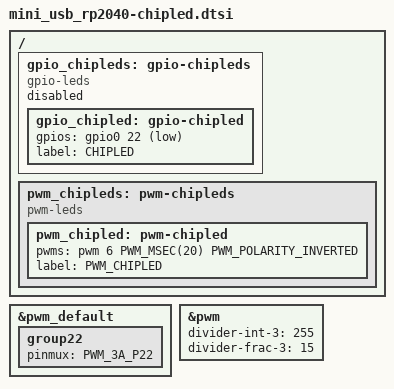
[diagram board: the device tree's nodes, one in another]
/*
 * Copyright (c) 2025 TiaC Systems
 * SPDX-License-Identifier: Apache-2.0
 */

#include <zephyr/dt-bindings/gpio/gpio.h>
#include <zephyr/dt-bindings/pwm/pwm.h>

/ {
	gpio_chipleds: gpio-chipleds {
		compatible = "gpio-leds";
		status = "disabled";
		gpio_chipled: gpio-chipled {
			gpios = <&gpio0 22 GPIO_ACTIVE_LOW>;
			label = "CHIPLED";
		};
	};

	pwm_chipleds: pwm-chipleds {
		compatible = "pwm-leds";
		status = "okay";
		pwm_chipled: pwm-chipled {
			pwms = <&pwm 6 PWM_MSEC(20) PWM_POLARITY_INVERTED>;
			label = "PWM_CHIPLED";
		};
	};
};

&pwm_default {
	group22 {
		pinmux = <PWM_3A_P22>;
	};
};

&pwm {
	status = "okay";
	divider-int-3 = <255>;
	divider-frac-3 = <15>;
};
